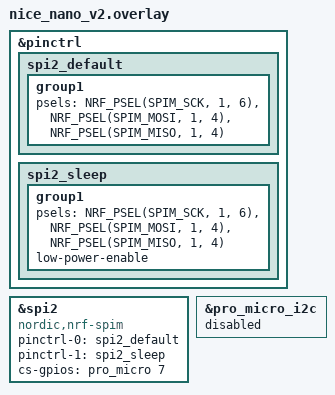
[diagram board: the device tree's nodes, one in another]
/*
 * Copyright (c) 2022 The ZMK Contributors
 *
 * SPDX-License-Identifier: MIT
 */

&pinctrl {
    spi2_default: spi2_default {
        group1 {
            psels = <NRF_PSEL(SPIM_SCK, 1, 6)>,
                    <NRF_PSEL(SPIM_MOSI, 1, 4)>,
                    <NRF_PSEL(SPIM_MISO, 1, 4)>;
        };
    };

    spi2_sleep: spi2_sleep {
        group1 {
            psels = <NRF_PSEL(SPIM_SCK, 1, 6)>,
                    <NRF_PSEL(SPIM_MOSI, 1, 4)>,
                    <NRF_PSEL(SPIM_MISO, 1, 4)>;
            low-power-enable;
        };
    };
};

nice_view_spi: &spi2 {
    compatible = "nordic,nrf-spim";
    pinctrl-0 = <&spi2_default>;
    pinctrl-1 = <&spi2_sleep>;
    pinctrl-names = "default", "sleep";
    cs-gpios = <&pro_micro 7 GPIO_ACTIVE_HIGH>;
};

&pro_micro_i2c {
    status = "disabled";
};
